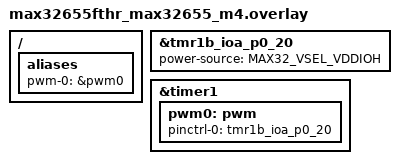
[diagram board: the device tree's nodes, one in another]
/*
 * Copyright (c) 2023-2024 Analog Devices, Inc.
 *
 * SPDX-License-Identifier: Apache-2.0
 */

/ {
	aliases {
		pwm-0 = &pwm0;
	};
};

&tmr1b_ioa_p0_20 {
	power-source=<MAX32_VSEL_VDDIOH>;
};

&timer1 {
	status = "okay";
	pwm0: pwm {
		status = "okay";
		pinctrl-0 = <&tmr1b_ioa_p0_20>;
		pinctrl-names = "default";
	};
};
